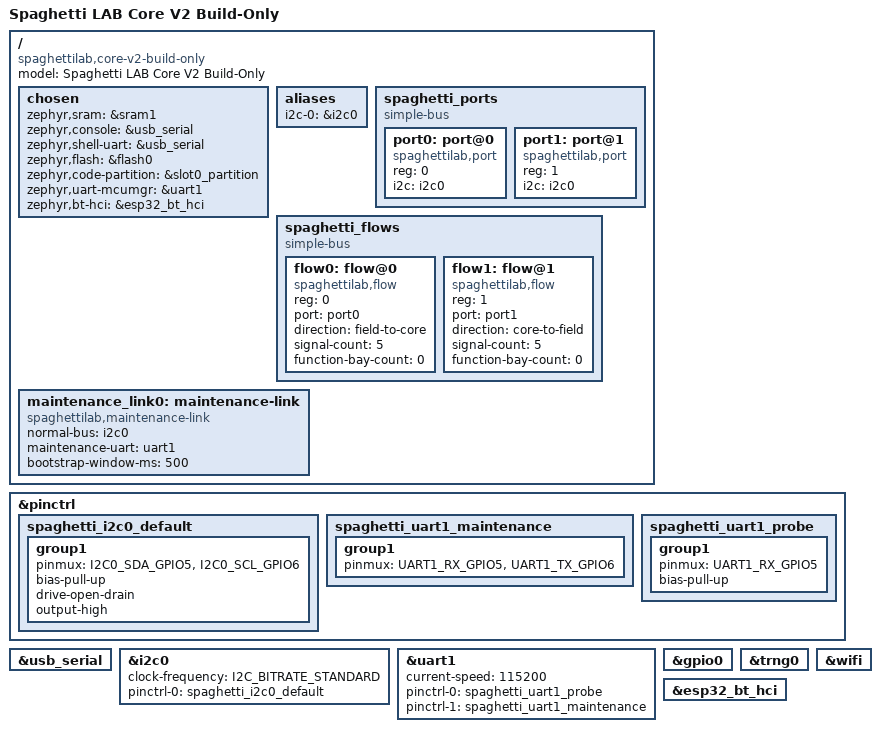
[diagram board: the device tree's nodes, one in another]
/*
 * Build-only topology. Pin and connector assignments are simulated and must
 * not be used to flash physical hardware.
 */

/dts-v1/;

#include <espressif/esp32c3/esp32c3_mini_n4.dtsi>
#include <espressif/partitions_0x0_default.dtsi>
#include <zephyr/dt-bindings/pinctrl/esp-pinctrl-common.h>
#include <zephyr/dt-bindings/pinctrl/esp32c3-pinctrl.h>
#include <zephyr/dt-bindings/pinctrl/esp32c3-gpio-sigmap.h>

/ {
	model = "Spaghetti LAB Core V2 Build-Only";
	compatible = "spaghettilab,core-v2-build-only", "espressif,esp32c3";

	chosen {
		zephyr,sram = &sram1;
		zephyr,console = &usb_serial;
		zephyr,shell-uart = &usb_serial;
		zephyr,flash = &flash0;
		zephyr,code-partition = &slot0_partition;
		zephyr,uart-mcumgr = &uart1;
		zephyr,bt-hci = &esp32_bt_hci;
	};

	aliases {
		i2c-0 = &i2c0;
	};

	spaghetti_ports {
		compatible = "simple-bus";
		#address-cells = <1>;
		#size-cells = <0>;

		port0: port@0 {
			compatible = "spaghettilab,port";
			reg = <0>;
			i2c = <&i2c0>;
			status = "okay";
		};

		port1: port@1 {
			compatible = "spaghettilab,port";
			reg = <1>;
			i2c = <&i2c0>;
			status = "okay";
		};
	};

	spaghetti_flows {
		compatible = "simple-bus";
		#address-cells = <1>;
		#size-cells = <0>;

		flow0: flow@0 {
			compatible = "spaghettilab,flow";
			reg = <0>;
			port = <&port0>;
			direction = "field-to-core";
			signal-count = <5>;
			function-bay-count = <0>;
			status = "okay";
		};

		flow1: flow@1 {
			compatible = "spaghettilab,flow";
			reg = <1>;
			port = <&port1>;
			direction = "core-to-field";
			signal-count = <5>;
			function-bay-count = <0>;
			status = "okay";
		};
	};

	maintenance_link0: maintenance-link {
		compatible = "spaghettilab,maintenance-link";
		normal-bus = <&i2c0>;
		maintenance-uart = <&uart1>;
		bootstrap-window-ms = <500>;
		status = "okay";
	};
};

&pinctrl {
	spaghetti_i2c0_default: spaghetti_i2c0_default {
		group1 {
			pinmux = <I2C0_SDA_GPIO5>, <I2C0_SCL_GPIO6>;
			bias-pull-up;
			drive-open-drain;
			output-high;
		};
	};

	spaghetti_uart1_maintenance: spaghetti_uart1_maintenance {
		group1 {
			pinmux = <UART1_RX_GPIO5>, <UART1_TX_GPIO6>;
		};
	};

	spaghetti_uart1_probe: spaghetti_uart1_probe {
		group1 {
			pinmux = <UART1_RX_GPIO5>;
			bias-pull-up;
		};
	};
};

&usb_serial {
	status = "okay";
};

&i2c0 {
	status = "okay";
	clock-frequency = <I2C_BITRATE_STANDARD>;
	pinctrl-0 = <&spaghetti_i2c0_default>;
	pinctrl-names = "default";
};

&uart1 {
	status = "okay";
	current-speed = <115200>;
	pinctrl-0 = <&spaghetti_uart1_probe>;
	pinctrl-1 = <&spaghetti_uart1_maintenance>;
	pinctrl-names = "default", "sleep";
};

&gpio0 {
	status = "okay";
};

&trng0 {
	status = "okay";
};

&wifi {
	status = "okay";
};

&esp32_bt_hci {
	status = "okay";
};
